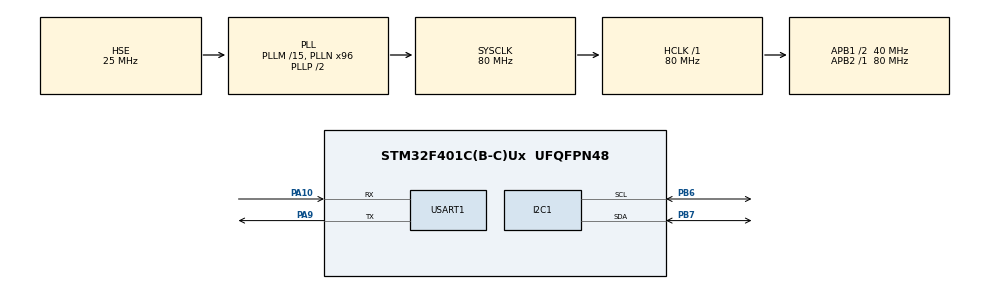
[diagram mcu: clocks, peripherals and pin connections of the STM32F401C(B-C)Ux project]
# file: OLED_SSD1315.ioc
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I2C1.I2C_Mode=I2C_Standard
Mcu.Family=STM32F4
Mcu.Name=STM32F401C(B-C)Ux
Mcu.Package=UFQFPN48
NVIC.PriorityGroup=NVIC_PRIORITYGROUP_4
PA10.Mode=Asynchronous
PA10.Signal=USART1_RX
PA13.Mode=Serial_Wire
PA13.Signal=SYS_JTMS-SWDIO
PA14.Mode=Serial_Wire
PA14.Signal=SYS_JTCK-SWCLK
PA9.Mode=Asynchronous
PA9.Signal=USART1_TX
PB6.Mode=I2C
PB6.Signal=I2C1_SCL
PB7.Mode=I2C
PB7.Signal=I2C1_SDA
PH0\ -\ OSC_IN.Mode=HSE-External-Oscillator
PH0\ -\ OSC_IN.Signal=RCC_OSC_IN
PH1\ -\ OSC_OUT.Mode=HSE-External-Oscillator
PH1\ -\ OSC_OUT.Signal=RCC_OSC_OUT
ProjectManager.HeapSize=0x200
ProjectManager.StackSize=0x400
ProjectManager.TargetToolchain=MDK-ARM V5.32
RCC.48MHZClocksFreq_Value=40000000
RCC.AHBFreq_Value=80000000
RCC.APB1CLKDivider=RCC_HCLK_DIV2
RCC.APB1Freq_Value=40000000
RCC.APB1TimFreq_Value=80000000
RCC.APB2Freq_Value=80000000
RCC.APB2TimFreq_Value=80000000
RCC.CortexFreq_Value=80000000
RCC.HCLKFreq_Value=80000000
RCC.HSE_VALUE=25000000
RCC.HSI_VALUE=16000000
RCC.LSE_VALUE=32768
RCC.PLLM=15
RCC.PLLN=96
RCC.PLLSourceVirtual=RCC_PLLSOURCE_HSE
RCC.SYSCLKFreq_VALUE=80000000
RCC.SYSCLKSource=RCC_SYSCLKSOURCE_PLLCLK
RCC.VCOOutputFreq_Value=160000000
USART1.VirtualMode=VM_ASYNC
VP_CRC_VS_CRC.Mode=CRC_Activate
board=custom

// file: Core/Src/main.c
/* USER CODE BEGIN Header */
/**
  ******************************************************************************
  * @file           : main.c
  * @brief          : Main program body
  ******************************************************************************
  * @attention
  *
  * Copyright (c) 2025 STMicroelectronics.
  * All rights reserved.
  *
  * This software is licensed under terms that can be found in the LICENSE file
  * in the root directory of this software component.
  * If no LICENSE file comes with this software, it is provided AS-IS.
  *
  ******************************************************************************
  */
/* USER CODE END Header */
#include "main.h"
#include "crc.h"
#include "i2c.h"
#include "usart.h"
#include "gpio.h"

/* USER CODE BEGIN Includes */
#include "oled.h"
#include "stdio.h"
#include "display_ui.h"
/* USER CODE END Includes */

void SystemClock_Config(void);

/* USER CODE BEGIN 0 */
uint32_t value = 0;
extern const unsigned char Image_saber[512];
extern UI_Button_t button0;
/* USER CODE END 0 */

int main(void)
{

  /* MCU Configuration--------------------------------------------------------*/

  /* Reset of all peripherals, Initializes the Flash interface and the Systick. */
  HAL_Init();

  /* Configure the system clock */
  SystemClock_Config();

  /* Initialize all configured peripherals */
  MX_GPIO_Init();
  MX_I2C1_Init();
  MX_CRC_Init();
  MX_USART1_UART_Init();
  /* USER CODE BEGIN 2 */
  OLED_Init();

//	HAL_UART_Transmit(&huart1,"Hello",sizeof("Hello"),100);
  /* USER CODE END 2 */

  /* Infinite loop */
  /* USER CODE BEGIN WHILE */
  while (1)
  {
		OLED_FillScreen(OLED_OFF);
		UI_DrawButton(&button0);
		OLED_RefreshScreen();
		HAL_Delay(500);

//		// OLED 绘制函数 普通测试
//		OLED_FillScreen(OLED_OFF);
//		OLED_DrawLine(0, 63, 0, 31, OLED_ON, OLED_Nor);
//		OLED_DrawRectangle(64, 127, 0, 31, OLED_ON, OLED_Nor);
//		OLED_DrawQuarterArc(64, 48, 10, Quarter1|Quarter2, OLED_ON, OLED_Nor);
//		OLED_DrawQuarterSector(64, 48, 10, Quarter3|Quarter4, OLED_ON, OLED_Nor);
//		OLED_RefreshScreen();
//		HAL_Delay(500);

//		// OLED 绘制函数 Xor测试
//		OLED_FillScreen(OLED_OFF);
//		OLED_DrawQuarterArc(64, 48, 10, Quarter1|Quarter2, OLED_ON, OLED_Nor);
//		OLED_DrawQuarterSector(64, 48, 10, Quarter3|Quarter4, OLED_ON, OLED_Nor);
//		OLED_DrawLine(0, 63, 0, 31, OLED_ON, OLED_Xor);
//		OLED_DrawRectangle(48, 127, 0, 63, OLED_ON, OLED_Xor);
//		OLED_RefreshScreen();
//		HAL_Delay(500);

//		// OLED 绘制函数 过边界测试
//		OLED_FillScreen(OLED_OFF);
//		OLED_DrawQuarterArc(64, 48, 20, Quarter1|Quarter2, OLED_ON);
//		OLED_DrawQuarterSector(64, 48, 20, Quarter3|Quarter4, OLED_ON);
//		OLED_DrawLine(0, 127, 0, 63+64, OLED_ON, OLED_Xor);
//		OLED_DrawRectangle(100, 127+16, 0, 31, OLED_ON, OLED_Xor);
//		OLED_RefreshScreen();
//		HAL_Delay(500);

//		// OLED 绘制函数 过边界测试
//		OLED_FillScreen(OLED_OFF);
//		OLED_DrawString(64,  0, "Hello!", &Font_8x16_consolas, FONT_Regular, OLED_ON, OLED_Nor);
//		OLED_DrawString(64, 16, "Hello!", &Font_8x16_consolas, FONT_UNDERLINE, OLED_ON, OLED_Nor);
//		OLED_DrawImage(0, 0, 63, 63, Image_saber, OLED_ON, OLED_Nor);
//		OLED_RefreshScreen();
//		HAL_Delay(500);

    /* USER CODE END WHILE */

  }
}

void SystemClock_Config(void)
{
  RCC_OscInitTypeDef RCC_OscInitStruct = {0};
  RCC_ClkInitTypeDef RCC_ClkInitStruct = {0};

  /** Configure the main internal regulator output voltage
  */
  __HAL_RCC_PWR_CLK_ENABLE();
  __HAL_PWR_VOLTAGESCALING_CONFIG(PWR_REGULATOR_VOLTAGE_SCALE2);

  /** Initializes the RCC Oscillators according to the specified parameters
  * in the RCC_OscInitTypeDef structure.
  */
  RCC_OscInitStruct.OscillatorType = RCC_OSCILLATORTYPE_HSE;
  RCC_OscInitStruct.HSEState = RCC_HSE_ON;
  RCC_OscInitStruct.PLL.PLLState = RCC_PLL_ON;
  RCC_OscInitStruct.PLL.PLLSource = RCC_PLLSOURCE_HSE;
  RCC_OscInitStruct.PLL.PLLM = 15;
  RCC_OscInitStruct.PLL.PLLN = 96;
  RCC_OscInitStruct.PLL.PLLP = RCC_PLLP_DIV2;
  RCC_OscInitStruct.PLL.PLLQ = 4;
  if (HAL_RCC_OscConfig(&RCC_OscInitStruct) != HAL_OK)
  {
    Error_Handler();
  }

  /** Initializes the CPU, AHB and APB buses clocks
  */
  RCC_ClkInitStruct.ClockType = RCC_CLOCKTYPE_HCLK|RCC_CLOCKTYPE_SYSCLK
                              |RCC_CLOCKTYPE_PCLK1|RCC_CLOCKTYPE_PCLK2;
  RCC_ClkInitStruct.SYSCLKSource = RCC_SYSCLKSOURCE_PLLCLK;
  RCC_ClkInitStruct.AHBCLKDivider = RCC_SYSCLK_DIV1;
  RCC_ClkInitStruct.APB1CLKDivider = RCC_HCLK_DIV2;
  RCC_ClkInitStruct.APB2CLKDivider = RCC_HCLK_DIV1;

  if (HAL_RCC_ClockConfig(&RCC_ClkInitStruct, FLASH_LATENCY_2) != HAL_OK)
  {
    Error_Handler();
  }
}

void Error_Handler(void)
{
  __disable_irq();
  while (1)
  {
  }
}
